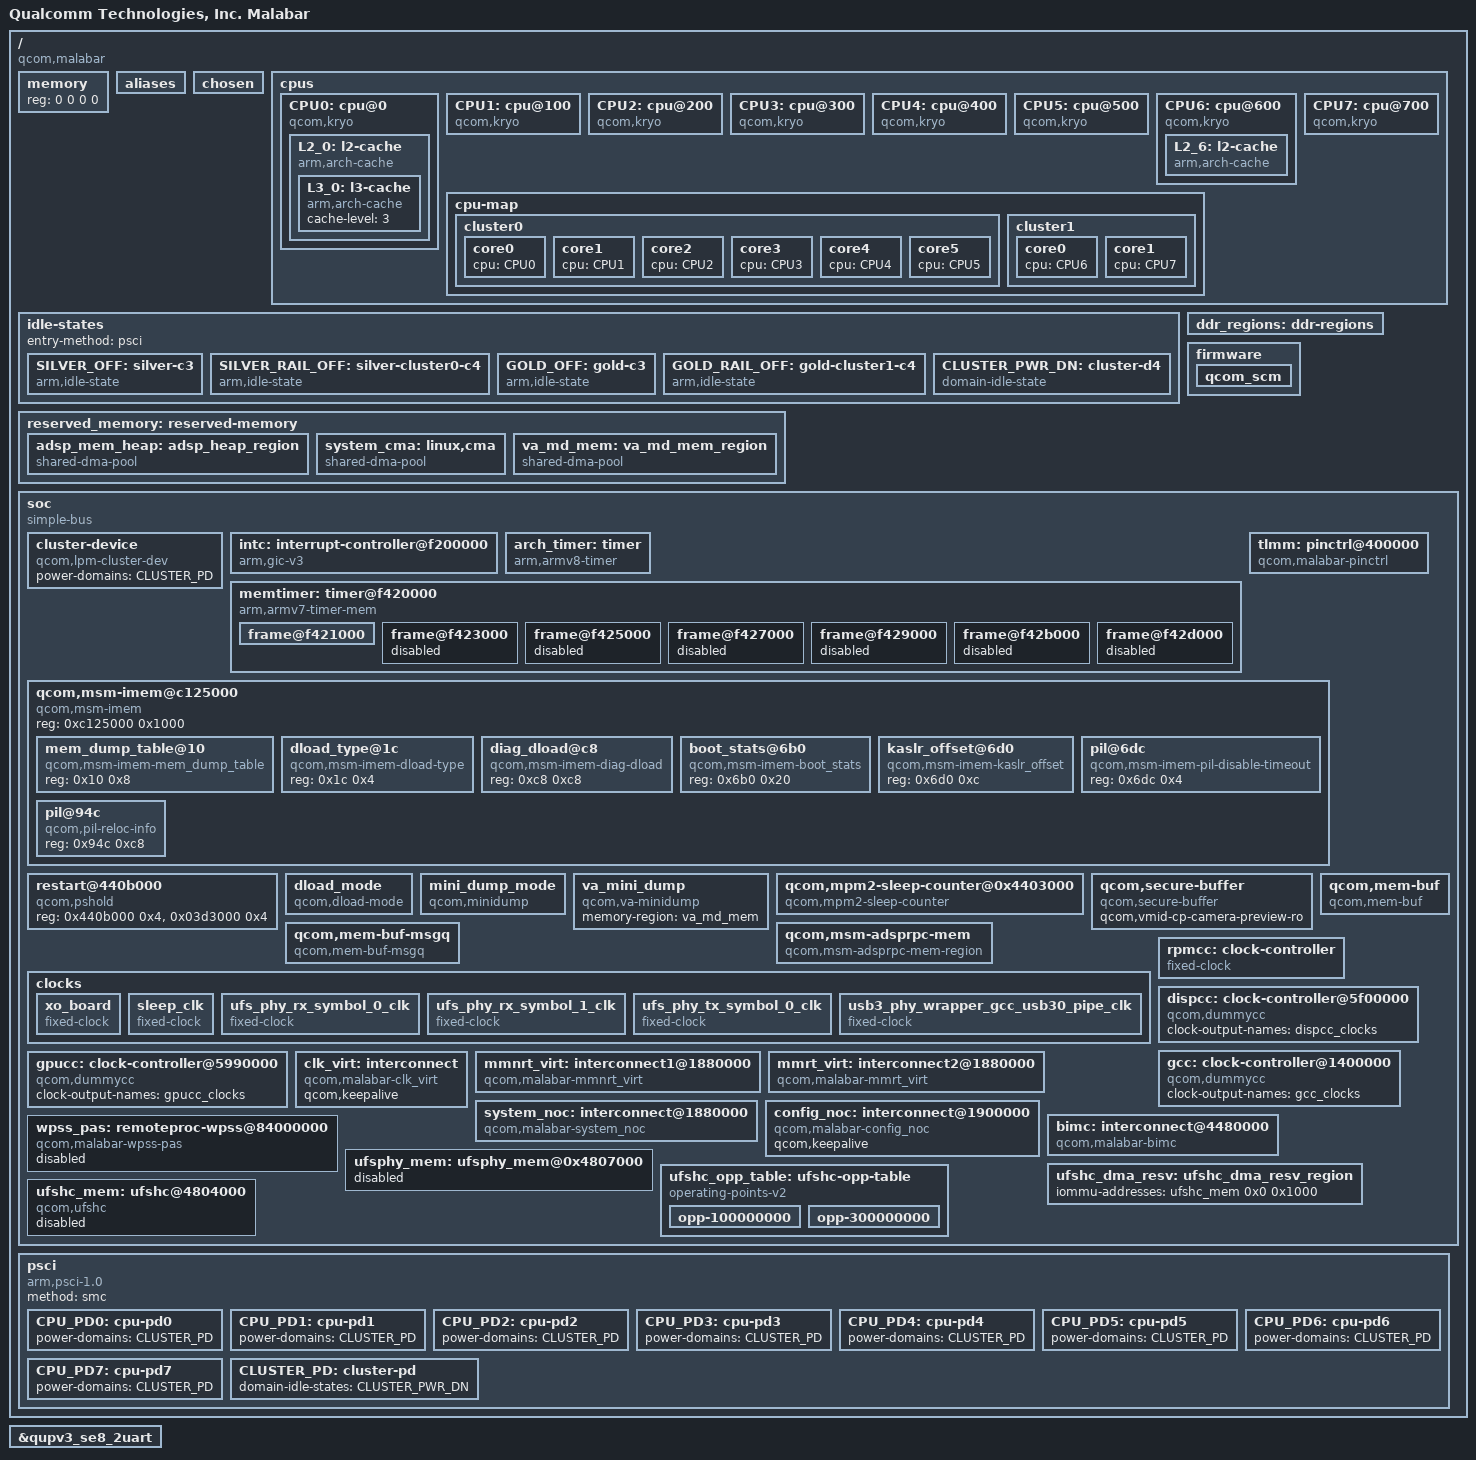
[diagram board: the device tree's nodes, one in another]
// SPDX-License-Identifier: BSD-3-Clause
/*
 * Copyright (c) Qualcomm Technologies, Inc. and/or its subsidiaries.
 */
#include <dt-bindings/interrupt-controller/arm-gic.h>
#include <dt-bindings/clock/qcom,rpmcc.h>
#include <dt-bindings/clock/qcom,malabar-dispcc.h>
#include <dt-bindings/clock/qcom,malabar-gcc.h>
#include <dt-bindings/clock/qcom,malabar-gpucc.h>
#include <dt-bindings/interconnect/qcom,icc.h>
#include <dt-bindings/interconnect/qcom,malabar.h>
#include <dt-bindings/gpio/gpio.h>

/ {
	model = "Qualcomm Technologies, Inc. Malabar";
	compatible = "qcom,malabar";
	qcom,msm-id = <733 0x10000>;
	interrupt-parent = <&intc>;

	#address-cells = <2>;
	#size-cells = <2>;
	memory { device_type = "memory"; reg = <0 0 0 0>; };

	aliases {
		serial0 = &qupv3_se8_2uart;
		ufshc1 = &ufshc_mem; /* Embedded UFS Slot */
	 };

	chosen: chosen {
		bootargs = "nokaslr kpti=0 log_buf_len=256K swiotlb=0 loop.max_part=7 swiotlb=0 kasan=off cgroup_disable=pressure android_arch_task_struct_size=512 cgroup.memory=nokmem,nosocket disable_dma32=on page_poison=on restrict_cma_redirect=false";
	};

	cpus {
		#address-cells = <2>;
		#size-cells = <0>;

		CPU0: cpu@0 {
			device_type = "cpu";
			compatible = "qcom,kryo";
			reg = <0x0 0x0>;
			enable-method = "psci";
			cpu-idle-states = <&SILVER_OFF &SILVER_RAIL_OFF>;
			power-domains = <&CPU_PD0>;
			power-domain-names = "psci";
			next-level-cache = <&L2_0>;
			capacity-dmips-mhz = <1024>;
			dynamic-power-coefficient = <100>;
			L2_0: l2-cache {
			      compatible = "arm,arch-cache";
			      cache-level = <2>;
			      next-level-cache = <&L3_0>;

				L3_0: l3-cache {
					compatible = "arm,arch-cache";
					cache-level = <3>;
				};
			};
		};

		CPU1: cpu@100 {
			device_type = "cpu";
			compatible = "qcom,kryo";
			reg = <0x0 0x100>;
			enable-method = "psci";
			cpu-idle-states = <&SILVER_OFF &SILVER_RAIL_OFF>;
			power-domains = <&CPU_PD1>;
			power-domain-names = "psci";
			capacity-dmips-mhz = <1024>;
			dynamic-power-coefficient = <100>;
			next-level-cache = <&L2_0>;
		};

		CPU2: cpu@200 {
			device_type = "cpu";
			compatible = "qcom,kryo";
			reg = <0x0 0x200>;
			enable-method = "psci";
			cpu-idle-states = <&SILVER_OFF &SILVER_RAIL_OFF>;
			power-domains = <&CPU_PD2>;
			power-domain-names = "psci";
			capacity-dmips-mhz = <1024>;
			dynamic-power-coefficient = <100>;
			next-level-cache = <&L2_0>;
		};

		CPU3: cpu@300 {
			device_type = "cpu";
			compatible = "qcom,kryo";
			reg = <0x0 0x300>;
			enable-method = "psci";
			cpu-idle-states = <&SILVER_OFF &SILVER_RAIL_OFF>;
			power-domains = <&CPU_PD3>;
			power-domain-names = "psci";
			capacity-dmips-mhz = <1024>;
			dynamic-power-coefficient = <100>;
			next-level-cache = <&L2_0>;
		};

		CPU4: cpu@400 {
			device_type = "cpu";
			compatible = "qcom,kryo";
			reg = <0x0 0x400>;
			enable-method = "psci";
			cpu-idle-states = <&SILVER_OFF &SILVER_RAIL_OFF>;
			power-domains = <&CPU_PD4>;
			power-domain-names = "psci";
			capacity-dmips-mhz = <1024>;
			dynamic-power-coefficient = <100>;
			next-level-cache = <&L2_0>;
		};

		CPU5: cpu@500 {
			device_type = "cpu";
			compatible = "qcom,kryo";
			reg = <0x0 0x500>;
			enable-method = "psci";
			cpu-idle-states = <&SILVER_OFF &SILVER_RAIL_OFF>;
			power-domains = <&CPU_PD5>;
			power-domain-names = "psci";
			capacity-dmips-mhz = <1024>;
			dynamic-power-coefficient = <100>;
			next-level-cache = <&L2_0>;
		};

		CPU6: cpu@600 {
			device_type = "cpu";
			compatible = "qcom,kryo";
			reg = <0x0 0x600>;
			enable-method = "psci";
			cpu-idle-states = <&GOLD_OFF &GOLD_RAIL_OFF>;
			power-domains = <&CPU_PD6>;
			power-domain-names = "psci";
			capacity-dmips-mhz = <1946>;
			dynamic-power-coefficient = <489>;
			next-level-cache = <&L2_6>;
			L2_6: l2-cache {
			      compatible = "arm,arch-cache";
			      cache-level = <2>;
			      next-level-cache = <&L3_0>;
			};
		};

		CPU7: cpu@700 {
			device_type = "cpu";
			compatible = "qcom,kryo";
			reg = <0x0 0x700>;
			enable-method = "psci";
			cpu-idle-states = <&GOLD_OFF &GOLD_RAIL_OFF>;
			power-domains = <&CPU_PD7>;
			power-domain-names = "psci";
			capacity-dmips-mhz = <1946>;
			dynamic-power-coefficient = <489>;
			next-level-cache = <&L2_6>;
		};

		cpu-map {
			cluster0 {
				core0 {
					cpu = <&CPU0>;
				};

				core1 {
					cpu = <&CPU1>;
				};

				core2 {
					cpu = <&CPU2>;
				};

				core3 {
					cpu = <&CPU3>;
				};

				core4 {
					cpu = <&CPU4>;
				};

				core5 {
					cpu = <&CPU5>;
				};
			};

			cluster1 {
				core0 {
					cpu = <&CPU6>;
				};

				core1 {
					cpu = <&CPU7>;
				};
			};
		};
	};

	idle-states {
		entry-method = "psci";

		SILVER_OFF: silver-c3 {  /* C3 */
			compatible = "arm,idle-state";
			idle-state-name = "pc";
			entry-latency-us = <549>;
			exit-latency-us = <901>;
			min-residency-us = <1774>;
			arm,psci-suspend-param = <0x40000003>;
			local-timer-stop;
		};

		SILVER_RAIL_OFF: silver-cluster0-c4 { /* C4 */
			compatible = "arm,idle-state";
			idle-state-name = "rail-pc";
			entry-latency-us = <702>;
			exit-latency-us = <915>;
			min-residency-us = <4001>;
			arm,psci-suspend-param = <0x40000004>;
			local-timer-stop;
		};

		GOLD_OFF: gold-c3 {  /* C3 */
			compatible = "arm,idle-state";
			idle-state-name = "pc";
			entry-latency-us = <523>;
			exit-latency-us = <1244>;
			min-residency-us = <2207>;
			arm,psci-suspend-param = <0x40000003>;
			local-timer-stop;
		};

		GOLD_RAIL_OFF: gold-cluster1-c4 { /* C4 */
			compatible = "arm,idle-state";
			idle-state-name = "rail-pc";
			entry-latency-us = <526>;
			exit-latency-us = <1854>;
			min-residency-us = <5555>;
			arm,psci-suspend-param = <0x40000004>;
			local-timer-stop;
		};

		CLUSTER_PWR_DN: cluster-d4 { /* D4 */
			compatible = "domain-idle-state";
			idle-state-name = "l3-pc";
			entry-latency-us = <2752>;
			exit-latency-us = <3038>;
			min-residency-us = <6118>;
			arm,psci-suspend-param = <0x41000044>;
		};
	};

	ddr_regions: ddr-regions { };

	firmware: firmware {
		qcom_scm: qcom_scm { };
	};

	reserved_memory: reserved-memory { };

	soc: soc { };

	psci {
		compatible = "arm,psci-1.0";
		method = "smc";

		CPU_PD0: cpu-pd0 {
			#power-domain-cells = <0>;
			power-domains = <&CLUSTER_PD>;
		};

		CPU_PD1: cpu-pd1 {
			#power-domain-cells = <0>;
			power-domains = <&CLUSTER_PD>;
		};

		CPU_PD2: cpu-pd2 {
			#power-domain-cells = <0>;
			power-domains = <&CLUSTER_PD>;
		};

		CPU_PD3: cpu-pd3 {
			#power-domain-cells = <0>;
			power-domains = <&CLUSTER_PD>;
		};

		CPU_PD4: cpu-pd4 {
			#power-domain-cells = <0>;
			power-domains = <&CLUSTER_PD>;
		};

		CPU_PD5: cpu-pd5 {
			#power-domain-cells = <0>;
			power-domains = <&CLUSTER_PD>;
		};

		CPU_PD6: cpu-pd6 {
			#power-domain-cells = <0>;
			power-domains = <&CLUSTER_PD>;
		};

		CPU_PD7: cpu-pd7 {
			#power-domain-cells = <0>;
			power-domains = <&CLUSTER_PD>;
		};

		CLUSTER_PD: cluster-pd {
			#power-domain-cells = <0>;
			domain-idle-states = <&CLUSTER_PWR_DN>;
		};
	};
};

#include "malabar-reserved-memory.dtsi"
#include "msm-arm-smmu-malabar.dtsi"
#include "malabar-dma-heaps.dtsi"

&reserved_memory {
	#address-cells = <2>;
	#size-cells = <2>;
	ranges;

	adsp_mem_heap: adsp_heap_region {
		compatible = "shared-dma-pool";
		alloc-ranges = <0x0 0x00000000 0x0 0xffffffff>;
		reusable;
		alignment = <0x0 0x400000>;
		size = <0x0 0xC00000>;
	};

	/* global autoconfigured region for contiguous allocations */
	system_cma: linux,cma {
		compatible = "shared-dma-pool";
		alloc-ranges = <0x0 0x00000000 0x0 0xffffffff>;
		reusable;
		alignment = <0x0 0x400000>;
		size = <0x0 0x2000000>;
		linux,cma-default;
	};

	va_md_mem: va_md_mem_region {
		compatible = "shared-dma-pool";
		alloc-ranges = <0x0 0x00000000 0x0 0xffffffff>;
		reusable;
		size = <0 0x1000000>;
	};
};

&soc {
	#address-cells = <1>;
	#size-cells = <1>;
	ranges = <0 0 0 0xffffffff>;
	compatible = "simple-bus";

	cluster-device {
		compatible = "qcom,lpm-cluster-dev";
		power-domains = <&CLUSTER_PD>;
	};

	intc: interrupt-controller@f200000 {
		compatible = "arm,gic-v3";
		#interrupt-cells = <3>;
		interrupt-controller;
		#redistributor-regions = <1>;
		redistributor-stride = <0x0 0x20000>;
		reg = <0xf200000 0x10000>,     /* GICD */
		      <0xf240000 0x100000>;    /* GICR * 8 */
		interrupts = <GIC_PPI 8 IRQ_TYPE_LEVEL_HIGH>;
	};

	arch_timer: timer {
		compatible = "arm,armv8-timer";
		interrupts = <GIC_PPI 1 (GIC_CPU_MASK_SIMPLE(8) | IRQ_TYPE_LEVEL_LOW)>,
			     <GIC_PPI 2 (GIC_CPU_MASK_SIMPLE(8) | IRQ_TYPE_LEVEL_LOW)>,
			     <GIC_PPI 3 (GIC_CPU_MASK_SIMPLE(8) | IRQ_TYPE_LEVEL_LOW)>,
			     <GIC_PPI 0 (GIC_CPU_MASK_SIMPLE(8) | IRQ_TYPE_LEVEL_LOW)>;
		clock-frequency = <19200000>;
	};

	memtimer: timer@f420000 {
		#address-cells = <1>;
		#size-cells = <1>;
		ranges;
		compatible = "arm,armv7-timer-mem";
		reg = <0x0f420000 0x1000>;
		clock-frequency = <19200000>;

		frame@f421000 {
			frame-number = <0>;
			interrupts = <GIC_SPI 8 IRQ_TYPE_LEVEL_HIGH>,
				     <GIC_SPI 6 IRQ_TYPE_LEVEL_HIGH>;
			reg = <0x0f421000 0x1000>,
			      <0x0f422000 0x1000>;
		};

		frame@f423000 {
			frame-number = <1>;
			interrupts = <GIC_SPI 9 IRQ_TYPE_LEVEL_HIGH>;
			reg = <0xf243000 0x1000>;
			status = "disabled";
		};

		frame@f425000 {
			frame-number = <2>;
			interrupts = <GIC_SPI 10 IRQ_TYPE_LEVEL_HIGH>;
			reg = <0xf425000 0x1000>;
			status = "disabled";
		};

		frame@f427000 {
			frame-number = <3>;
			interrupts = <GIC_SPI 11 IRQ_TYPE_LEVEL_HIGH>;
			reg = <0xf427000 0x1000>;
			status = "disabled";
		};

		frame@f429000 {
			frame-number = <4>;
			interrupts = <GIC_SPI 12 IRQ_TYPE_LEVEL_HIGH>;
			reg = <0xf429000 0x1000>;
			status = "disabled";
		};

		frame@f42b000 {
			frame-number = <5>;
			interrupts = <GIC_SPI 13 IRQ_TYPE_LEVEL_HIGH>;
			reg = <0xf42b000 0x1000>;
			status = "disabled";
		};

		frame@f42d000 {
			frame-number = <6>;
			interrupts = <GIC_SPI 14 IRQ_TYPE_LEVEL_HIGH>;
			reg = <0xf42d000 0x1000>;
			status = "disabled";
		};
	};

	tlmm: pinctrl@400000 {
		compatible = "qcom,malabar-pinctrl";
		reg = <0x400000 0x1000000>;
		interrupts = <GIC_SPI 227 IRQ_TYPE_LEVEL_HIGH>;
		gpio-controller;
		#gpio-cells = <2>;
		interrupt-controller;
		#interrupt-cells = <2>;
	};

	qcom,msm-imem@c125000 {
		compatible = "qcom,msm-imem";
		reg = <0xc125000 0x1000>;
		ranges = <0x0 0xc125000 0x1000>;
		#address-cells = <1>;
		#size-cells = <1>;

		mem_dump_table@10 {
			compatible = "qcom,msm-imem-mem_dump_table";
			reg = <0x10 0x8>;
		};

		dload_type@1c {
			compatible = "qcom,msm-imem-dload-type";
			reg = <0x1c 0x4>;
		};

		diag_dload@c8 {
			compatible = "qcom,msm-imem-diag-dload";
			reg = <0xc8 0xc8>;
		};

		boot_stats@6b0 {
			compatible = "qcom,msm-imem-boot_stats";
			reg = <0x6b0 0x20>;
		};

		kaslr_offset@6d0 {
			compatible = "qcom,msm-imem-kaslr_offset";
			reg = <0x6d0 0xc>;
		};

		pil@6dc {
			compatible = "qcom,msm-imem-pil-disable-timeout";
			reg = <0x6dc 0x4>;
		};

		pil@94c {
			compatible = "qcom,pil-reloc-info";
			reg = <0x94c 0xc8>;
		};
	};

	restart@440b000 {
		compatible = "qcom,pshold";
		reg = <0x440b000 0x4>, <0x03d3000 0x4>;
		reg-names = "pshold-base", "tcsr-boot-misc-detect";
	};

	dload_mode {
		compatible = "qcom,dload-mode";
	};

	mini_dump_mode {
		compatible = "qcom,minidump";
	};

	va_mini_dump {
		compatible = "qcom,va-minidump";
		memory-region = <&va_md_mem>;
	};

	qcom,mpm2-sleep-counter@0x4403000 {
		compatible = "qcom,mpm2-sleep-counter";
		reg = <0x4403000 0x1000>;
		clock-frequency = <32768>;
	};

	qcom,secure-buffer {
		compatible = "qcom,secure-buffer";
		qcom,vmid-cp-camera-preview-ro;
	};

	qcom,mem-buf {
		compatible = "qcom,mem-buf";
		qcom,mem-buf-capabilities = "supplier";
		qcom,vmid = <3>;
	};

	qcom,mem-buf-msgq {
		compatible = "qcom,mem-buf-msgq";
	};

	qcom,msm-adsprpc-mem {
		compatible = "qcom,msm-adsprpc-mem-region";
		memory-region = <&adsp_mem_heap>;
		restrict-access;
	};

	clocks {
		xo_board: xo_board {
			compatible = "fixed-clock";
			clock-frequency = <19200000>;
			clock-output-names = "xo_board";
			#clock-cells = <0>;
		};

		sleep_clk: sleep_clk {
			compatible = "fixed-clock";
			clock-frequency = <32000>;
			clock-output-names = "sleep_clk";
			#clock-cells = <0>;
		};

		ufs_phy_rx_symbol_0_clk: ufs_phy_rx_symbol_0_clk {
			compatible = "fixed-clock";
			clock-frequency = <1000>;
			clock-output-names = "ufs_phy_rx_symbol_0_clk";
			#clock-cells = <0>;
		};

		ufs_phy_rx_symbol_1_clk: ufs_phy_rx_symbol_1_clk {
			compatible = "fixed-clock";
			clock-frequency = <1000>;
			clock-output-names = "ufs_phy_rx_symbol_1_clk";
			#clock-cells = <0>;
		};

		ufs_phy_tx_symbol_0_clk: ufs_phy_tx_symbol_0_clk {
			compatible = "fixed-clock";
			clock-frequency = <1000>;
			clock-output-names = "ufs_phy_tx_symbol_0_clk";
			#clock-cells = <0>;
		};

		usb3_phy_wrapper_gcc_usb30_pipe_clk: usb3_phy_wrapper_gcc_usb30_pipe_clk {
			compatible = "fixed-clock";
			clock-frequency = <1000>;
			clock-output-names = "usb3_phy_wrapper_gcc_usb30_pipe_clk";
			#clock-cells = <0>;
		};
	};

	rpmcc: clock-controller {
		compatible = "fixed-clock";
		clock-output-names = "rpm_clocks";
		clock-frequency = <19200000>;
		#clock-cells = <1>;
	};

	dispcc: clock-controller@5f00000 {
		compatible = "qcom,dummycc";
		clock-output-names = "dispcc_clocks";
		#clock-cells = <1>;
		#reset-cells = <1>;
		#power-domain-cells = <1>;
	};

	gcc: clock-controller@1400000 {
		compatible = "qcom,dummycc";
		clock-output-names = "gcc_clocks";
		#clock-cells = <1>;
		#reset-cells = <1>;
		#power-domain-cells = <1>;
	};

	gpucc: clock-controller@5990000 {
		compatible = "qcom,dummycc";
		clock-output-names = "gpucc_clocks";
		#clock-cells = <1>;
		#reset-cells = <1>;
		#power-domain-cells = <1>;
	};

	clk_virt: interconnect {
		compatible = "qcom,malabar-clk_virt";
		#interconnect-cells = <1>;
		qcom,keepalive;
	};

	mmnrt_virt: interconnect1@1880000 {
		reg = <0x01880000 0x57600>;
		compatible = "qcom,malabar-mmnrt_virt";
		#interconnect-cells = <1>;
		qcom,util-factor = <142>;
		qcom,keepalive;
	};

	mmrt_virt: interconnect2@1880000 {
		reg = <0x01880000 0x57600>;
		compatible = "qcom,malabar-mmrt_virt";
		#interconnect-cells = <1>;
		qcom,util-factor = <142>;
		qcom,keepalive;
	};

	system_noc: interconnect@1880000 {
		reg = <0x01880000 0x57600>;
		compatible = "qcom,malabar-system_noc";
		#interconnect-cells = <1>;
		qcom,keepalive;
	};

	config_noc: interconnect@1900000 {
		compatible = "qcom,malabar-config_noc";
		#interconnect-cells = <1>;
		qcom,keepalive;
	};

	bimc: interconnect@4480000 {
		compatible = "qcom,malabar-bimc";
		#interconnect-cells = <1>;
		qcom,util-factor = <151>;
		qcom,keepalive;
	};

	wpss_pas: remoteproc-wpss@84000000 {
		compatible = "qcom,malabar-wpss-pas";
		reg = <0x84000000 0x10000>;

		status = "disabled";

		memory-region = <&wpss_mem>;
		firmware-name = "adrastea/wpss.mdt";
	};

	ufsphy_mem: ufsphy_mem@0x4807000 {
		#address-cells = <1>;
		#size-cells = <1>;
		reg = <0x4807000 0xE10>;
		reg-names = "phy_mem";
		#phy-cells = <0>;

		lanes-per-direction = <2>;
		clock-names = "ref_clk_src",
			"ref_aux_clk", "qref_clk", "ref_clk_pad_en",
			"rx_sym0_mux_clk", "rx_sym1_mux_clk", "tx_sym0_mux_clk",
			"rx_sym0_phy_clk", "rx_sym1_phy_clk", "tx_sym0_phy_clk";
		clocks = <&rpmcc RPM_SMD_XO_CLK_SRC>,
			<&gcc GCC_UFS_PHY_PHY_AUX_CLK>,
			<&gcc GCC_UFS_CLKREF_EN>,
			<&gcc GCC_UFS_PAD_CLKREF_EN>,
			<&gcc GCC_UFS_PHY_RX_SYMBOL_0_CLK_SRC>,
			<&gcc GCC_UFS_PHY_RX_SYMBOL_1_CLK_SRC>,
			<&gcc GCC_UFS_PHY_TX_SYMBOL_0_CLK_SRC>,
			<&ufs_phy_rx_symbol_0_clk>,
			<&ufs_phy_rx_symbol_1_clk>,
			<&ufs_phy_tx_symbol_0_clk>;
		resets = <&ufshc_mem 0>;
		status = "disabled";
	};

	ufshc_dma_resv: ufshc_dma_resv_region {
		/*
		 * Restrict IOVA mappings for UFSHC buffers to the 3 GB region
		 * from 0x1000 - 0xffffffff.
		 */
		iommu-addresses = <&ufshc_mem 0x0 0x1000>;
	};

	ufshc_opp_table: ufshc-opp-table {
		compatible = "operating-points-v2";

		// LOW_SVS
		opp-100000000 {
			opp-hz = /bits/ 64 <75000000>,
				 /bits/ 64 <0>,
				 /bits/ 64 <0>,
				 /bits/ 64 <75000000>,
				 /bits/ 64 <100000000>,
				 /bits/ 64 <0>,
				 /bits/ 64 <0>,
				 /bits/ 64 <0>,
				 /bits/ 64 <0>;
		};

		// NOM/TURBO
		opp-300000000 {
			opp-hz = /bits/ 64 <300000000>,
				 /bits/ 64 <0>,
				 /bits/ 64 <0>,
				 /bits/ 64 <300000000>,
				 /bits/ 64 <403000000>,
				 /bits/ 64 <0>,
				 /bits/ 64 <0>,
				 /bits/ 64 <0>,
				 /bits/ 64 <0>;
		};
	};

	ufshc_mem: ufshc@4804000 {
		compatible = "qcom,ufshc";
		#address-cells = <1>;
		#size-cells = <1>;
		reg = <0x4804000 0x3000>;
		reg-names = "ufs_mem";

		interrupts = <GIC_SPI 356 IRQ_TYPE_LEVEL_HIGH>;
		phys = <&ufsphy_mem>;
		phy-names = "ufsphy";
		#reset-cells = <1>;

		power-domains = <&gcc GCC_UFS_PHY_GDSC>;
		lanes-per-direction = <2>;

		clock-names =
			"core_clk",
			"bus_aggr_clk",
			"iface_clk",
			"core_clk_unipro",
			"core_clk_ice",
			"ref_clk",
			"tx_lane0_sync_clk",
			"rx_lane0_sync_clk",
			"rx_lane1_sync_clk";
		clocks =
			<&gcc GCC_UFS_PHY_AXI_CLK>,
			<&gcc GCC_SYS_NOC_UFS_PHY_AXI_CLK>,
			<&gcc GCC_UFS_PHY_AHB_CLK>,
			<&gcc GCC_UFS_PHY_UNIPRO_CORE_CLK>,
			<&gcc GCC_UFS_PHY_ICE_CORE_CLK>,
			<&rpmcc RPM_SMD_XO_CLK_SRC>,
			<&gcc GCC_UFS_PHY_TX_SYMBOL_0_CLK>,
			<&gcc GCC_UFS_PHY_RX_SYMBOL_0_CLK>,
			<&gcc GCC_UFS_PHY_RX_SYMBOL_1_CLK>;

		operating-points-v2 = <&ufshc_opp_table>;
		interconnects = <&system_noc MASTER_UFS_MEM &bimc SLAVE_EBI_CH0>,
				<&bimc MASTER_AMPSS_M0 &config_noc SLAVE_UFS_MEM_CFG>;
		interconnect-names = "ufs-ddr", "cpu-ufs";

		iommus = <&apps_smmu 0x0180 0x0>;
		qcom,iommu-dma = "fastmap";
		memory-region = <&ufshc_dma_resv>;

		reset-gpios = <&tlmm 114 GPIO_ACTIVE_LOW>;
		resets = <&gcc GCC_UFS_PHY_BCR>;
		reset-names = "rst";

		qcom,bypass-pbl-rst-wa;
		qcom,max-cpus = <8>;
		status = "disabled";
	};
};

#include "malabar-coresight.dtsi"
#include "malabar-debug.dtsi"
#include "malabar-stub-regulators.dtsi"
#include "malabar-pinctrl.dtsi"
#include "malabar-qupv3.dtsi"

&qupv3_se8_2uart {
	status = "ok";
};

#include "malabar-usb.dtsi"
